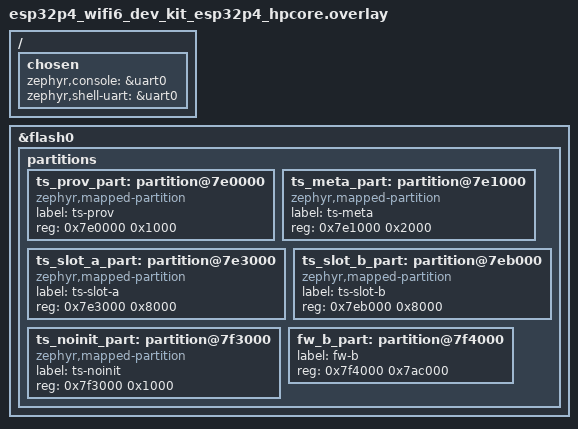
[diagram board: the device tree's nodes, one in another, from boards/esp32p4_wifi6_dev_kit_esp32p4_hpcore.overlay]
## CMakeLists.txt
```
# SPDX-License-Identifier: Apache-2.0
cmake_minimum_required(VERSION 3.20.0)
find_package(Zephyr REQUIRED HINTS $ENV{ZEPHYR_BASE})
project(tessera_p4bench)

# P4-W2（V0.14.0）网络面：凭据经 cmake 凭据文件注入（仓外纪律——命令行
# -D 会进 west 错误回显〔p4wifibench 实测教训〕，故走 include 文件，600）：
#   west build ... -- -DEXTRA_CONF_FILE=p4net.conf \
#                    -DP4BENCH_CREDS_FILE=/tmp/p4b_creds.cmake
# 凭据文件形态：set(P4BENCH_WIFI_SSID "...") + set(P4BENCH_WIFI_PASSWORD "...")
# 提供凭据 = 网络面激活（P4BENCH_NET 编入 main.c WiFi/DHCP 块 + P4W2* 判据行）；
# 不提供 = p4bench 既有无网持久链形态（TS_NET=n 基线零变化）。
if(DEFINED P4BENCH_CREDS_FILE)
  include(${P4BENCH_CREDS_FILE})
endif()
if(P4BENCH_WIFI_SSID)
  target_compile_definitions(app PRIVATE
    P4BENCH_NET=1
    P4BENCH_WIFI_SSID="${P4BENCH_WIFI_SSID}"
    P4BENCH_WIFI_PASSWORD="${P4BENCH_WIFI_PASSWORD}")
endif()

target_sources(app PRIVATE src/main.c)
```

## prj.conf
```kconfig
# SPDX-License-Identifier: Apache-2.0
# p4bench（P4 适配批）：persistbench 源级复用——P4 板 bring-up 判据
# 首启 = 烧录会话（TS_TEST prov 注入通道〔合同 10：写通道仅烧录期/测试构建〕
# + 分步安装链 + activate）→ 暖复位；此后每次复位 = 全部状态出自 flash。
CONFIG_PRINTK=y
CONFIG_TS_CORE=y
CONFIG_TS_SAFETY=y
CONFIG_TS_APP_WAMR=y
CONFIG_TS_TEST=y
# 本基准无网面（板级四已测）：关 ts-net，避免 linkmon 无传输时按合同 3
# 将通道压入 linkloss 态（真机已观测该行为正确生效——留痕报告）。
CONFIG_TS_NET=n
CONFIG_FLASH=y
CONFIG_FLASH_MAP=y
CONFIG_TS_STORE_FLASH=y
CONFIG_REBOOT=y
# 主线程降优先级（boardbench 同款：APP 线程 10 优先投递，校验线程轮询不饿死）
CONFIG_MAIN_THREAD_PRIORITY=15
```

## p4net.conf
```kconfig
# SPDX-License-Identifier: Apache-2.0
# P4-W2（V0.14.0）网络面追加 conf——EXTRA_CONF_FILE 注入（缺省 p4bench 保持
# 无网形态不变：TS_NET=n 持久链判据不受扰）。WiFi = esp_hosted_mcu 新驱动
# （P4-W1 p4wifibench 同款已验链）；zenoh = TS_NET_ZENOH（RCVTIMEO/SNDTIMEO
# 由 Kconfig select 兜底——R2 教训）。
CONFIG_TS_NET=y
CONFIG_TS_NET_ZENOH=y
CONFIG_ZENOH_PICO=y
CONFIG_ZENOH_PICO_PUBLICATION=y
CONFIG_ZENOH_PICO_SUBSCRIPTION=y
CONFIG_ZENOH_PICO_QUERYABLE=y
CONFIG_ZENOH_PICO_LINK_TCP=y
CONFIG_ZENOH_PICO_LINK_UDP_UNICAST=y
CONFIG_ZENOH_PICO_MULTI_THREAD=y
CONFIG_NETWORKING=y
CONFIG_NET_IPV4=y
CONFIG_NET_UDP=y
CONFIG_NET_TCP=y
CONFIG_NET_DHCPV4=y
CONFIG_NET_MGMT=y
CONFIG_NET_MGMT_EVENT=y
CONFIG_WIFI=y
CONFIG_WIFI_ESP_HOSTED_MCU=y
# FIX-1/R1 族纪律（rx ≥4096——驱动缺省 2560）+ R2（sysworkq ≥4096）+ R2 时代
# 上下文面（NET_MAX_CONTEXTS 权威 = 4）
CONFIG_NET_RX_STACK_SIZE=4096
CONFIG_SYSTEM_WORKQUEUE_STACK_SIZE=4096
CONFIG_NET_MAX_CONTEXTS=4
CONFIG_LOG=y
CONFIG_LOG_MODE_IMMEDIATE=y
# zenoh-pico Zephyr 平台 = pthread 族（atkbench/netbench 同款面）
CONFIG_POSIX_API=y
CONFIG_POSIX_THREAD_THREADS_MAX=8
CONFIG_MAX_PTHREAD_MUTEX_COUNT=16
CONFIG_MAX_PTHREAD_COND_COUNT=16
CONFIG_DYNAMIC_THREAD=y
CONFIG_DYNAMIC_THREAD_STACK_SIZE=8192
CONFIG_DYNAMIC_THREAD_POOL_SIZE=4
CONFIG_THREAD_STACK_INFO=y
# 系统堆（zenoh-pico z_malloc 走 k_malloc 系统堆——4096 缺省 = z_open
# rc=-78 OOM 实测）。48KB = sram0_0_seg 余量实测推算（131072 溢出 79968B
# → 头 room ≈51KB；PSRAM 重平随板级批）。z_open 实测域 ≈20-30KB 内绰绰）
CONFIG_HEAP_MEM_POOL_SIZE=49152
```

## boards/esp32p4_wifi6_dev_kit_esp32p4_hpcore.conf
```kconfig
# SPDX-License-Identifier: Apache-2.0
# P4 bring-up 板级片段（ESP32-P4-WIFI6-DEV-KIT，Waveshare）：内存面与 S3
# persistbench 同过渡值（PSRAM 挂接前；DEC-23/27）。P4 HP SRAM 充裕，
# 后续批按 HLD §4.6 每板动态预算再定值。
CONFIG_TS_STORE_SLOT_SIZE=32768
CONFIG_TS_APP_THREAD_STACK=16384
# RV32 调用帧比 Xtensa 深：4096 main 栈在安装链（meta 读 → slot 擦写）
# 实测溢出（sp 越栈底 0x230，Illegal instruction @ 表数据）。8192 实测定值。
CONFIG_MAIN_STACK_SIZE=8192
```

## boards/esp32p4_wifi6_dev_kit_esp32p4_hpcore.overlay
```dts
/*
 * P4 适配批（板级 bring-up）：ESP32-P4-WIFI6-DEV-KIT（Waveshare，16MB flash，
 * HP 核 RISC-V @ 400MHz 双核）。板目标 = esp32p4_wifi6_dev_kit/esp32p4/hpcore
 * （v4.5 斜杠限定语法）。
 * console 重指 uart0：板载 CH343 桥 = COM/UART Type-C 口（esptool 下载模式
 * 固定走 UART0 实测即此口）；板默认 usb_serial 需另接 USB 口——单线判据
 * 走 CH343。
 * ts-store 五分区 carved 自 4.5 默认 16M 布局 slot1 区（0x7e0000..0xfa0000，
 * 7936KB）：boot/sys/slot0/lpcore/storage/coredump 原样保留（esptool 偏移零
 * 变化）；slot1 删除并以 ts 五分区 + fw-b 预留替代（persistbench 同语义，
 * DEC-23）。分区 4KB 对齐 = esp32p4 擦除块；compatible = zephyr,mapped-
 * partition = v4.5 PARTITION_ID 宏要求（教训 30）。
 * 尺寸耦合：slot = CONFIG_TS_STORE_SLOT_SIZE（本板 conf = 32768；part.c
 * BUILD_ASSERT 把关）。
 */
/ {
	chosen {
		zephyr,console = &uart0;
		zephyr,shell-uart = &uart0;
	};
};

/delete-node/ &slot1_partition;

&flash0 {
	partitions {
		ts_prov_part: partition@7e0000 {
			compatible = "zephyr,mapped-partition";
			label = "ts-prov";
			reg = <0x7e0000 0x1000>;
		};
		ts_meta_part: partition@7e1000 {
			compatible = "zephyr,mapped-partition";
			label = "ts-meta";
			reg = <0x7e1000 0x2000>;
		};
		ts_slot_a_part: partition@7e3000 {
			compatible = "zephyr,mapped-partition";
			label = "ts-slot-a";
			reg = <0x7e3000 0x8000>;
		};
		ts_slot_b_part: partition@7eb000 {
			compatible = "zephyr,mapped-partition";
			label = "ts-slot-b";
			reg = <0x7eb000 0x8000>;
		};
		ts_noinit_part: partition@7f3000 {
			compatible = "zephyr,mapped-partition";
			label = "ts-noinit";
			reg = <0x7f3000 0x1000>;
		};
		/* fw-b：未来 MCUmgr 固件第二 slot 预留（DEC-23；V1 未接线） */
		fw_b_part: partition@7f4000 {
			label = "fw-b";
			reg = <0x7f4000 0x7ac000>;
		};
	};
};
```

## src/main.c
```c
/* SPDX-License-Identifier: Apache-2.0 */
/*
 * persistbench（板级五）：prov/APP/meta flash 持久化验证（docs/board-persist.md）。
 * 流程：
 *   首启（prov 缺失）= 烧录会话：P4B1 prov 注入（TS_TEST 通道）→ P4B2 分步
 *   安装链（stage_begin/chunk/verify/activate——与 sys/app-* 网络命令同一
 *   内部链）→ 暖复位；
 *   此后每次复位：P4B3 全框架自举（prov/meta/slot 全部出自 flash）→
 *   P4B5 APP 自举运行 + 写路径全链验证 → P4B PASS。
 */
#include <string.h>
#include <zephyr/kernel.h>
#include <zephyr/sys/reboot.h>
#include <ts/appmgr.h>
#include <ts/core.h>
#include <ts/hal.h>
#include <ts/safety.h>
#include <ts/store.h>
#include <ts/tsap.h>
#include "../../../module/tessera/src/net/internal.h" /* ts_cbor_* 构造助手 */

#ifdef P4BENCH_NET
/* P4-W2（V0.14.0）网络面：WiFi STA（esp_hosted_mcu 新驱动）+ DHCPv4。
 * atkbench 同型（main 前置联网——zenoh glue 自举时链路已备）；凭据经
 * CMake 凭据文件编入（仓外纪律）。判据行：P4W2 WIFI UP / P4W2 DHCP OK。
 * 失败不 abort——继续走框架流（zenoh 面如实离线，日志可辨）。 */
#include <zephyr/net/net_if.h>
#include <zephyr/net/net_event.h>
#include <zephyr/net/wifi_mgmt.h>
#include <zephyr/net/dhcpv4.h>

#ifndef P4BENCH_WIFI_SSID
#define P4BENCH_WIFI_SSID ""
#endif

static struct net_mgmt_event_callback p4b_ip_cb;
static struct k_sem p4b_ip_sem;

static void p4b_ip_handler(struct net_mgmt_event_callback *cb, uint64_t mgmt,
			   struct net_if *iface)
{
	ARG_UNUSED(cb);
	ARG_UNUSED(iface);
	if (mgmt == NET_EVENT_IPV4_ADDR_ADD) {
		k_sem_give(&p4b_ip_sem);
	}
}

static void p4b_net_up(void)
{
	struct net_if *iface = net_if_get_default();

	for (int s = 0; s < 100 && !iface; s++) { /* 驱动 netif 注册等待 */
		k_sleep(K_MSEC(100));
		iface = net_if_get_default();
	}
	if (!iface) {
		printk("P4W2 WIFI FAIL no netif（无网形态继续）\n");
		return;
	}
	printk("P4W2 WIFI UP\n");

	k_sem_init(&p4b_ip_sem, 0, 1);
	net_mgmt_init_event_callback(&p4b_ip_cb, p4b_ip_handler,
				     NET_EVENT_IPV4_ADDR_ADD);
	net_mgmt_add_event_callback(&p4b_ip_cb);

	static const uint8_t ssid[] = P4BENCH_WIFI_SSID;
	static const uint8_t psk[] = P4BENCH_WIFI_PASSWORD;

	struct wifi_connect_req_params cnx = {
		.ssid = ssid,
		.ssid_length = sizeof(ssid) - 1,
		.psk = psk,
		.psk_length = sizeof(psk) - 1,
		.security = WIFI_SECURITY_TYPE_PSK,
		.channel = WIFI_CHANNEL_ANY,
		.band = WIFI_FREQ_BAND_2_4_GHZ,
		.mfp = WIFI_MFP_OPTIONAL,
	};
	int rc = net_mgmt(NET_REQUEST_WIFI_CONNECT, iface, &cnx, sizeof(cnx));
	printk("P4W2 wifi_connect rc=%d\n", rc);

	if (k_sem_take(&p4b_ip_sem, K_SECONDS(40)) == 0 && iface->config.ip.ipv4) {
		char ip[NET_IPV4_ADDR_LEN];

		net_addr_ntop(AF_INET,
			      &iface->config.ip.ipv4->unicast[0].ipv4.address.in_addr,
			      ip, sizeof(ip));
		printk("P4W2 DHCP OK ip=%s\n", ip);
	} else {
		printk("P4W2 DHCP FAIL（40s 无址——继续，zenoh 面将离线重试）\n");
	}
}
#endif /* P4BENCH_NET */

#include "p4bench_pkg.h" /* TSAP v2 包（gen_p4b_pkg.py 机械生成，测试根签名 */

/* ---- sim 通道（框架.app 同款：唯一写路径 → driver_dispatch → sim 记录）-- */

static const ts_out_ch_t pb_ch = {
	.uid = "pb0", .kind = TS_CH_GPIO,
	.poweron = {.b = false}, .linkloss = {.b = false}, .fault = {.b = false},
};
static const ts_hal_dev_desc_t pb_dev = {.uid = "pb0", .kind = TS_DEV_GPIO_OUT};

static bool pb_gpio(void)
{
	ts_out_value_t v;

	if (ts_safety_readback("pb0", &v) != TS_OK) {
		return false;
	}
	return v.b;
}

static bool pb_wait_gpio(bool want)
{
	for (int i = 0; i < 300; i++) {
		if (pb_gpio() == want) {
			return true;
		}
		k_msleep(10);
	}
	return false;
}

/* ---- prov CBOR（schema v1 定稿键序，DEC-30⑤；定长确定性编码）------------- */

#define CB_MAX 256

struct cb {
	uint8_t b[CB_MAX];
	uint32_t n;
};

static void cb_u8(struct cb *c, uint8_t v)
{
	c->b[c->n++] = v;
}

static void cb_hdr(struct cb *c, uint8_t mt, uint32_t val)
{
	if (val < 0x18) {
		cb_u8(c, (uint8_t)(mt | val));
	} else if (val <= 0xFF) {
		cb_u8(c, (uint8_t)(mt | 0x18));
		cb_u8(c, (uint8_t)val);
	} else {
		cb_u8(c, (uint8_t)(mt | 0x19));
		cb_u8(c, (uint8_t)(val >> 8));
		cb_u8(c, (uint8_t)val);
	}
}

static void cb_tstr(struct cb *c, const char *s)
{
	cb_hdr(c, 0x60, strlen(s));
	for (size_t i = 0; i < strlen(s); i++) {
		cb_u8(c, (uint8_t)s[i]);
	}
}

static size_t build_prov(struct cb *c)
{
	memset(c, 0, sizeof(*c));
	cb_hdr(c, 0xA0, 9);
	cb_tstr(c, "v");
	cb_hdr(c, 0x00, 1);
	cb_tstr(c, "node_id");
	cb_tstr(c, "pb-dev");
	cb_tstr(c, "cube_id");
	cb_tstr(c, "cube-pb");
	cb_tstr(c, "routers");
	cb_hdr(c, 0x80, 1);
	cb_tstr(c, "tcp/192.168.2.90:9955");
	cb_tstr(c, "pk0");
	cb_hdr(c, 0x40, 32);
	for (int i = 0; i < 32; i++) {
		cb_u8(c, 0x00);
	}
	cb_tstr(c, "pk1");
	cb_hdr(c, 0x40, 32);
	for (int i = 0; i < 32; i++) {
		cb_u8(c, 0x00);
	}
	cb_tstr(c, "cred");
	cb_tstr(c, "");
	cb_tstr(c, "pwr_ma");
	cb_hdr(c, 0x00, 500);
	cb_tstr(c, "estop");
	cb_hdr(c, 0x00, 1);
	return c->n;
}

/* ---- TSAP 容器（manifest canonical 七键 + 夹具 wasm + COSE 结构尾）-------- */

/* ---- 复位后验证线程（ts_core_boot 不返回，验证并发于框架运行期）---------- */

static int pb_perm_seen;

static void pb_on_perm(const ts_evt_t *e, void *u)
{
	ARG_UNUSED(e);
	ARG_UNUSED(u);
	pb_perm_seen++;
}

/* 链路声明（部署侧）：本基准 TS_NET=n（无网面），boot 步骤 2 poweron_init
 * 将通道压回 SAFE_POWERON 后无人驱动链路——正常部署由 linkmon 在传输
 * 确立后 set_link(true)（板级四实证）。此处 BOOT_DONE 后由 glue 声明，
 * 通道迁移 ACTIVE，此后 APP 写入可达（app_init 期写入落在 SAFE 态被拒
 * = 合同 1/3 冷启动语义，init_res=-4 为预期值）。 */
static void pb_on_boot_done(const ts_evt_t *e, void *u)
{
	ARG_UNUSED(e);
	ARG_UNUSED(u);
	ts_safety_set_link(true);
	printk("P4B4 boot done -> link up (glue, no-host bench)\n");
}

static void pb_verify(void *p1, void *p2, void *p3)
{
	ARG_UNUSED(p1);
	ARG_UNUSED(p2);
	ARG_UNUSED(p3);
	(void)ts_evt_subscribe(TS_EVT_PERM_DENIED, pb_on_perm, NULL);
	for (int i = 0; i < 600 && !ts_appmgr_app_running(); i++) {
		k_msleep(20);
	}
	if (!ts_appmgr_app_running()) {
		printk("P4B FAIL app not running after boot\n");
		return;
	}
	ts_app_info_t info;

	ts_appmgr_get_info(&info);
	printk("P4B5 app active: id=%s ver=%s slot=%u\n",
	       info.app_id, info.app_ver, info.active_slot);
	/* 诊断：init_res=-4（SAFE_POWERON 写拒绝）= 冷启动预期（见上）；此后
	 * evt 驱动写验证 ACTIVE 态全链。 */
	struct ts_app_rt_stats st;

	ts_appmgr_app_stats(&st);
	printk("P4B5 diag: init_res=%d evt_seen=%u health_fails=%u perm_seen=%d\n",
	       (int)st.init_res, st.evt_seen, st.health_fails, pb_perm_seen);
	if (ts_appmgr_app_evt(1) != TS_OK || !pb_wait_gpio(true)) {
		printk("P4B FAIL app_evt(1) write\n");
		return;
	}
	printk("P4B5 app_evt(1) -> gpio=1 (flash slot -> boot 装载 -> wasm 全链)\n");
	if (ts_appmgr_app_evt(0) == TS_OK && pb_wait_gpio(false)) {
		printk("P4B5 app_evt(0) -> gpio=0\n");
	} else {
		printk("P4B FAIL app_evt(0)\n");
		return;
	}
	printk("P4B PASS prov+meta+slot persisted across reset\n");
	for (;;) {
		k_msleep(5000);
		printk("P4B alive t=%u\n", (unsigned)k_uptime_get_32());
	}
}
K_THREAD_DEFINE(pb_verify_tid, 2048, pb_verify, NULL, NULL, NULL, 12, 0, 1000);

int main(void)
{
	printk("P4B0 persistbench\n");

#ifdef P4BENCH_NET
	p4b_net_up(); /* P4-W2：联网先行（zenoh glue 自举时链路已备） */
#endif

	ts_res_t lr = ts_store_prov_load();

	if (lr != TS_OK) {
		/* 首启 = 烧录会话（prov 缺失；合同 10 写通道 = 烧录期/测试构建注入） */
		printk("P4B1 first boot: prov absent (rc=%d) -> provision session\n", (int)lr);
		struct cb c;

		if (ts_store_prov_write_test(c.b, (uint32_t)build_prov(&c)) != TS_OK ||
		    ts_store_prov_load() != TS_OK) {
			printk("P4B FAIL prov\n");
			return 1;
		}
		printk("P4B1 prov burned: node=%s cube=%s\n",
		       ts_store_prov()->node_id, ts_store_prov()->cube_id);

		const uint8_t *pkg = p4bench_pkg;
		size_t total = sizeof(p4bench_pkg);
		uint8_t slot = 0;
		uint32_t hw = 0;
		const uint8_t root_key[32] = {0}; /* TEST：prov 根钥缺省（结构级验签） */

		if (total == 0) {
			printk("P4B FAIL install total=0\n");
			return 1;
		}
		/* 分步报码：失败面逐级可见（begin/chunk/verify 各自 r 码）*/
		ts_res_t sr = ts_appmgr_stage_begin((uint32_t)total, &slot);

		if (sr != TS_OK) {
			printk("P4B FAIL install begin r=%d\n", (int)sr);
			return 1;
		}
		ts_res_t cr = ts_appmgr_stage_chunk(0, pkg, (uint32_t)total, &hw);

		if (cr != TS_OK) {
			printk("P4B FAIL install chunk r=%d\n", (int)cr);
			return 1;
		}
		ts_res_t vr = ts_appmgr_stage_verify(root_key, NULL, NULL, NULL);

		if (vr != TS_OK) {
			printk("P4B FAIL install verify r=%d\n", (int)vr);
			return 1;
		}
		ts_app_info_t info;

		if (ts_appmgr_stage_activate(&info) != TS_OK) {
			printk("P4B FAIL activate\n");
			return 1;
		}
		printk("P4B2 app staged: slot=%u total=%u hw=%u -> warm reset\n",
		       slot, (unsigned)total, hw);
		sys_reboot(SYS_REBOOT_WARM);
	}

	printk("P4B3 boot: prov from flash node=%s\n", ts_store_prov()->node_id);
	if (ts_hal_register_dev(&pb_dev) != TS_OK ||
	    ts_safety_register_channel(&pb_ch) != TS_OK) {
		printk("P4B FAIL channel\n");
		return 1;
	}
	ts_safety_set_link(true);
	/* BOOT_DONE 订阅须在 boot 前完成（事件发布早于校验线程启动） */
	(void)ts_evt_subscribe(TS_EVT_BOOT_DONE, pb_on_boot_done, NULL);
	/* 全框架自举（步骤 8 = slot 装载）；不返回：成功进入主循环，
	 * 失败进 fail-safe 停喂 WDT（合同 6）。 */
	ts_core_boot();
}
```

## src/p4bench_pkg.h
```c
/* 机械生成（gen_p4b_pkg.py）——com.tessera.p4b-0.1.0.tsap，928B（TSAP v2 + 测试根签名；wasm = app/appw/native_app.wasm） */
static const uint8_t p4bench_pkg[928] = {
	0x54, 0x53, 0x41, 0x50, 0x00, 0x02, 0x00, 0x00, 0x00, 0x74, 0x00, 0x00,
	0x01, 0x1e, 0x00, 0x01, 0x75, 0xb0, 0x19, 0x9c, 0xad, 0x00, 0xbb, 0xff,
	0x0c, 0xb3, 0xec, 0x91, 0xff, 0x97, 0x51, 0xdd, 0xc5, 0x18, 0x8e, 0xba,
	0x25, 0xbe, 0x5e, 0xa8, 0x05, 0x9a, 0x1b, 0x06, 0xe4, 0x39, 0x8e, 0xe6,
	0xa7, 0x64, 0x63, 0x61, 0x70, 0x73, 0x81, 0x6e, 0x67, 0x70, 0x69, 0x6f,
	0x3a, 0x77, 0x72, 0x69, 0x74, 0x65, 0x3a, 0x30, 0x2d, 0x33, 0x66, 0x61,
	0x70, 0x70, 0x5f, 0x69, 0x64, 0x6f, 0x63, 0x6f, 0x6d, 0x2e, 0x74, 0x65,
	0x73, 0x73, 0x65, 0x72, 0x61, 0x2e, 0x70, 0x34, 0x62, 0x67, 0x61, 0x70,
	0x70, 0x5f, 0x76, 0x65, 0x72, 0x65, 0x30, 0x2e, 0x31, 0x2e, 0x30, 0x67,
	0x65, 0x78, 0x70, 0x6f, 0x72, 0x74, 0x73, 0x81, 0x6b, 0x68, 0x65, 0x61,
	0x6c, 0x74, 0x68, 0x5f, 0x70, 0x69, 0x6e, 0x67, 0x67, 0x68, 0x65, 0x61,
	0x70, 0x5f, 0x6b, 0x62, 0x08, 0x68, 0x73, 0x74, 0x61, 0x63, 0x6b, 0x5f,
	0x6b, 0x62, 0x04, 0x6a, 0x6d, 0x69, 0x6e, 0x5f, 0x66, 0x77, 0x5f, 0x76,
	0x65, 0x72, 0x65, 0x30, 0x2e, 0x30, 0x2e, 0x31, 0x00, 0x61, 0x73, 0x6d,
	0x01, 0x00, 0x00, 0x00, 0x01, 0x11, 0x03, 0x60, 0x03, 0x7f, 0x7f, 0x7f,
	0x01, 0x7f, 0x60, 0x01, 0x7f, 0x01, 0x7f, 0x60, 0x00, 0x01, 0x7f, 0x02,
	0x15, 0x01, 0x03, 0x65, 0x6e, 0x76, 0x0d, 0x74, 0x73, 0x5f, 0x67, 0x70,
	0x69, 0x6f, 0x5f, 0x77, 0x72, 0x69, 0x74, 0x65, 0x00, 0x00, 0x03, 0x06,
	0x05, 0x01, 0x01, 0x02, 0x02, 0x02, 0x04, 0x05, 0x01, 0x70, 0x01, 0x01,
	0x01, 0x05, 0x03, 0x01, 0x00, 0x02, 0x06, 0x08, 0x01, 0x7f, 0x01, 0x41,
	0x90, 0x88, 0x04, 0x0b, 0x07, 0x47, 0x06, 0x06, 0x6d, 0x65, 0x6d, 0x6f,
	0x72, 0x79, 0x02, 0x00, 0x08, 0x61, 0x70, 0x70, 0x5f, 0x69, 0x6e, 0x69,
	0x74, 0x00, 0x01, 0x07, 0x61, 0x70, 0x70, 0x5f, 0x65, 0x76, 0x74, 0x00,
	0x02, 0x08, 0x61, 0x70, 0x70, 0x5f, 0x74, 0x69, 0x63, 0x6b, 0x00, 0x03,
	0x0b, 0x68, 0x65, 0x61, 0x6c, 0x74, 0x68, 0x5f, 0x70, 0x69, 0x6e, 0x67,
	0x00, 0x04, 0x0c, 0x67, 0x65, 0x74, 0x5f, 0x6c, 0x61, 0x73, 0x74, 0x5f,
	0x65, 0x76, 0x74, 0x00, 0x05, 0x0a, 0x76, 0x05, 0x19, 0x00, 0x41, 0x00,
	0x20, 0x00, 0x36, 0x02, 0x84, 0x88, 0x80, 0x80, 0x00, 0x20, 0x00, 0x41,
	0x00, 0x41, 0x01, 0x10, 0x80, 0x80, 0x80, 0x80, 0x00, 0x0b, 0x3d, 0x00,
	0x02, 0x40, 0x20, 0x00, 0x41, 0x80, 0x02, 0x71, 0x45, 0x0d, 0x00, 0x41,
	0x00, 0x41, 0x01, 0x36, 0x02, 0x88, 0x88, 0x80, 0x80, 0x00, 0x41, 0x00,
	0x0f, 0x0b, 0x41, 0x00, 0x20, 0x00, 0x36, 0x02, 0x80, 0x88, 0x80, 0x80,
	0x00, 0x41, 0x00, 0x28, 0x02, 0x84, 0x88, 0x80, 0x80, 0x00, 0x41, 0x00,
	0x20, 0x00, 0x41, 0x01, 0x71, 0x10, 0x80, 0x80, 0x80, 0x80, 0x00, 0x0b,
	0x04, 0x00, 0x41, 0x00, 0x0b, 0x0b, 0x00, 0x41, 0x00, 0x28, 0x02, 0x88,
	0x88, 0x80, 0x80, 0x00, 0x0b, 0x0b, 0x00, 0x41, 0x00, 0x28, 0x02, 0x80,
	0x88, 0x80, 0x80, 0x00, 0x0b, 0x0b, 0x0b, 0x01, 0x00, 0x41, 0x80, 0x08,
	0x0b, 0x04, 0xff, 0xff, 0xff, 0xff, 0xd2, 0x84, 0x43, 0xa1, 0x01, 0x27,
	0xa0, 0x59, 0x01, 0x92, 0xa7, 0x64, 0x63, 0x61, 0x70, 0x73, 0x81, 0x6e,
	0x67, 0x70, 0x69, 0x6f, 0x3a, 0x77, 0x72, 0x69, 0x74, 0x65, 0x3a, 0x30,
	0x2d, 0x33, 0x66, 0x61, 0x70, 0x70, 0x5f, 0x69, 0x64, 0x6f, 0x63, 0x6f,
	0x6d, 0x2e, 0x74, 0x65, 0x73, 0x73, 0x65, 0x72, 0x61, 0x2e, 0x70, 0x34,
	0x62, 0x67, 0x61, 0x70, 0x70, 0x5f, 0x76, 0x65, 0x72, 0x65, 0x30, 0x2e,
	0x31, 0x2e, 0x30, 0x67, 0x65, 0x78, 0x70, 0x6f, 0x72, 0x74, 0x73, 0x81,
	0x6b, 0x68, 0x65, 0x61, 0x6c, 0x74, 0x68, 0x5f, 0x70, 0x69, 0x6e, 0x67,
	0x67, 0x68, 0x65, 0x61, 0x70, 0x5f, 0x6b, 0x62, 0x08, 0x68, 0x73, 0x74,
	0x61, 0x63, 0x6b, 0x5f, 0x6b, 0x62, 0x04, 0x6a, 0x6d, 0x69, 0x6e, 0x5f,
	0x66, 0x77, 0x5f, 0x76, 0x65, 0x72, 0x65, 0x30, 0x2e, 0x30, 0x2e, 0x31,
	0x00, 0x61, 0x73, 0x6d, 0x01, 0x00, 0x00, 0x00, 0x01, 0x11, 0x03, 0x60,
	0x03, 0x7f, 0x7f, 0x7f, 0x01, 0x7f, 0x60, 0x01, 0x7f, 0x01, 0x7f, 0x60,
	0x00, 0x01, 0x7f, 0x02, 0x15, 0x01, 0x03, 0x65, 0x6e, 0x76, 0x0d, 0x74,
	0x73, 0x5f, 0x67, 0x70, 0x69, 0x6f, 0x5f, 0x77, 0x72, 0x69, 0x74, 0x65,
	0x00, 0x00, 0x03, 0x06, 0x05, 0x01, 0x01, 0x02, 0x02, 0x02, 0x04, 0x05,
	0x01, 0x70, 0x01, 0x01, 0x01, 0x05, 0x03, 0x01, 0x00, 0x02, 0x06, 0x08,
	0x01, 0x7f, 0x01, 0x41, 0x90, 0x88, 0x04, 0x0b, 0x07, 0x47, 0x06, 0x06,
	0x6d, 0x65, 0x6d, 0x6f, 0x72, 0x79, 0x02, 0x00, 0x08, 0x61, 0x70, 0x70,
	0x5f, 0x69, 0x6e, 0x69, 0x74, 0x00, 0x01, 0x07, 0x61, 0x70, 0x70, 0x5f,
	0x65, 0x76, 0x74, 0x00, 0x02, 0x08, 0x61, 0x70, 0x70, 0x5f, 0x74, 0x69,
	0x63, 0x6b, 0x00, 0x03, 0x0b, 0x68, 0x65, 0x61, 0x6c, 0x74, 0x68, 0x5f,
	0x70, 0x69, 0x6e, 0x67, 0x00, 0x04, 0x0c, 0x67, 0x65, 0x74, 0x5f, 0x6c,
	0x61, 0x73, 0x74, 0x5f, 0x65, 0x76, 0x74, 0x00, 0x05, 0x0a, 0x76, 0x05,
	0x19, 0x00, 0x41, 0x00, 0x20, 0x00, 0x36, 0x02, 0x84, 0x88, 0x80, 0x80,
	0x00, 0x20, 0x00, 0x41, 0x00, 0x41, 0x01, 0x10, 0x80, 0x80, 0x80, 0x80,
	0x00, 0x0b, 0x3d, 0x00, 0x02, 0x40, 0x20, 0x00, 0x41, 0x80, 0x02, 0x71,
	0x45, 0x0d, 0x00, 0x41, 0x00, 0x41, 0x01, 0x36, 0x02, 0x88, 0x88, 0x80,
	0x80, 0x00, 0x41, 0x00, 0x0f, 0x0b, 0x41, 0x00, 0x20, 0x00, 0x36, 0x02,
	0x80, 0x88, 0x80, 0x80, 0x00, 0x41, 0x00, 0x28, 0x02, 0x84, 0x88, 0x80,
	0x80, 0x00, 0x41, 0x00, 0x20, 0x00, 0x41, 0x01, 0x71, 0x10, 0x80, 0x80,
	0x80, 0x80, 0x00, 0x0b, 0x04, 0x00, 0x41, 0x00, 0x0b, 0x0b, 0x00, 0x41,
	0x00, 0x28, 0x02, 0x88, 0x88, 0x80, 0x80, 0x00, 0x0b, 0x0b, 0x00, 0x41,
	0x00, 0x28, 0x02, 0x80, 0x88, 0x80, 0x80, 0x00, 0x0b, 0x0b, 0x0b, 0x01,
	0x00, 0x41, 0x80, 0x08, 0x0b, 0x04, 0xff, 0xff, 0xff, 0xff, 0x58, 0x40,
	0xdb, 0x58, 0x6c, 0x8f, 0x47, 0x62, 0x4a, 0x14, 0x90, 0x19, 0x63, 0xda,
	0x12, 0x99, 0x73, 0xe4, 0x5e, 0x81, 0xf3, 0xa6, 0x23, 0x50, 0x4f, 0xcd,
	0x68, 0x16, 0xfd, 0x33, 0x1e, 0x7c, 0x9a, 0x70, 0x8f, 0xe4, 0x02, 0xed,
	0x3d, 0x4d, 0xe9, 0x6e, 0x1f, 0x8b, 0xb8, 0x7a, 0x2f, 0x7d, 0x84, 0x3c,
	0x7c, 0x23, 0xb1, 0xb0, 0x3e, 0x39, 0x10, 0x34, 0xcc, 0x01, 0x3d, 0xb8,
	0x8e, 0xdb, 0xe1, 0x08,
};
```
